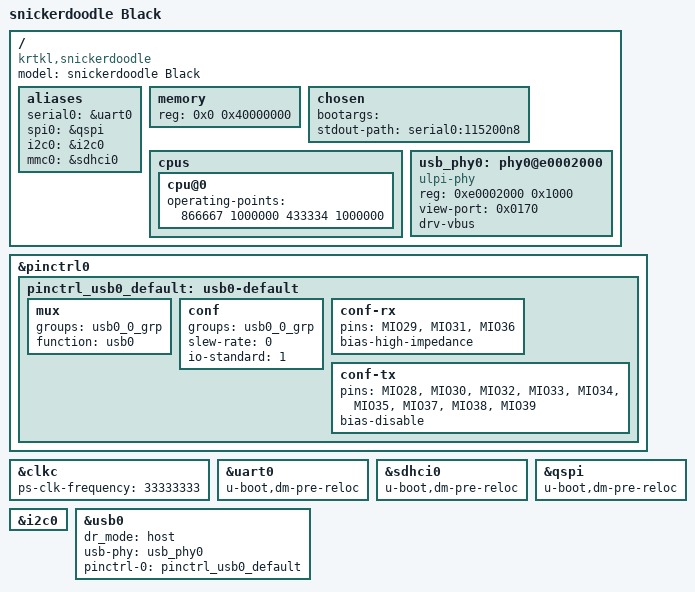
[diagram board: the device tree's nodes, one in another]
/*
 * snickerdoodle Black Development Platform
 *
 * Copyright (c) 2016 krtkl inc.
 *
 * SPDX-License-Identifier:     GPL-2.0+
 */


/dts-v1/;
/include/ "zynq-7000.dtsi"
/ {
        model = "snickerdoodle Black";
        compatible = "krtkl,snickerdoodle", "xlnx,zynq-7000";

	aliases {
		serial0 = &uart0;
		spi0 = &qspi;
		i2c0 = &i2c0;
		mmc0 = &sdhci0;
	};

	memory {
		device_type = "memory";
		reg = <0x0 0x40000000>;
	};

	chosen {
                bootargs = "";
                stdout-path = "serial0:115200n8";
        };

	cpus {
		cpu@0 {
			operating-points = <
				/* kHz	uV */
				866667	1000000
				433334	1000000
			>;
		};
	};

	usb_phy0: phy0@e0002000 {
		compatible = "ulpi-phy";
		#phy-cells = <0>;
		reg = <0xe0002000 0x1000>;
		view-port = <0x0170>;
		drv-vbus;
	};
};

&pinctrl0 {

	pinctrl_usb0_default: usb0-default {
		mux {
			groups = "usb0_0_grp";
			function = "usb0";
		};

		conf {
			groups = "usb0_0_grp";
			slew-rate = <0>;
			io-standard = <1>;
		};

		conf-rx {
			pins = "MIO29", "MIO31", "MIO36";
			bias-high-impedance;
		};

		conf-tx {
			pins = "MIO28", "MIO30", "MIO32", "MIO33", "MIO34",
			       "MIO35", "MIO37", "MIO38", "MIO39";
			bias-disable;
		};
	};
};

&clkc {
	ps-clk-frequency = <33333333>;
};

&uart0 {
	u-boot,dm-pre-reloc;
	status = "okay";
};

&sdhci0 {
	u-boot,dm-pre-reloc;
        status = "okay";
};

&qspi {
        u-boot,dm-pre-reloc;
        status = "okay";
};

&i2c0 {
		status = "okay";
};

&usb0 {
	status = "okay";
	dr_mode = "host";
	usb-phy = <&usb_phy0>;
	pinctrl-names = "default";
	pinctrl-0 = <&pinctrl_usb0_default>;
};
